# GD32G5x3 register map
File version: 1.0
CPU: CM33 r2p1, little endian, MPU, FPU, 4 interrupt priority bits
Registers are 32-bit, read-write, reset 0x0 unless marked. A register's access mark holds for its fields unless they carry their own. Offsets are from the block's base; [hi:lo] are bit positions; {n}, {i} and the like mark numbered series.

## HRTIMER_COMMON
Base 0x40015B80
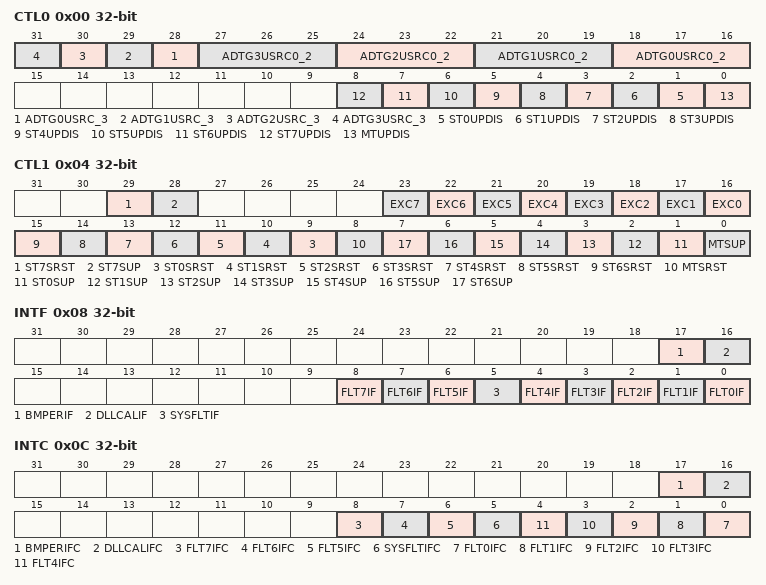
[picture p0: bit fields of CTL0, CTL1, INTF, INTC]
0x00 CTL0 — HRTIMER control register 0
  [n+28] ADTG{n}USRC_3 (n=0..3) — HRTIMER_ADTRIG{n} update source
  [3n+18:3n+16] ADTG{n}USRC0_2 (n=0..3) — HRTIMER_ADTRIG{n} update source
  [n+1] ST{n}UPDIS (n=0..7) — Slave_TIMER{n} update disable
  [0] MTUPDIS — Master_TIMER update disable
0x04 CTL1 — HRTIMER control register 1
  [29] ST7SRST — Slave_TIMER7 software reset
  [28] ST7SUP — Slave_TIMER7 software update
  [n+16] EXC{n} (n=0..7) — Exchange Slave_TIMER{n} outputs
  [n+9] ST{n}SRST (n=0..6) — Slave_TIMER{n} software reset
  [8] MTSRST — Master_TIMER software reset
  [n+1] ST{n}SUP (n=0..6) — Slave_TIMER{n} software update
  [0] MTSUP — Master_TIMER software update
0x08 INTF ro — HRTIMER interrupt flag register
  [17] BMPERIF — Bunch mode period interrupt flag
  [16] DLLCALIF — DLL calibration completed interrupt flag
  [8] FLT7IF — Fault 7 interrupt flag
  [7] FLT6IF — Fault 6 interrupt flag
  [6] FLT5IF — Fault 5 interrupt flag
  [5] SYSFLTIF — System fault interrupt flag
  [n] FLT{n}IF (n=0..4) — Fault {n} interrupt flag
0x0C INTC wo — HRTIMER interrupt flag clear register
  [17] BMPERIFC — Clear bunch mode period interrupt flag
  [16] DLLCALIFC — Clear DLL calibration completed interrupt flag
  [8] FLT7IFC — Clear fault 7 interrupt flag
  [7] FLT6IFC — Clear fault 6 interrupt flag
  [6] FLT5IFC — Clear fault 5 interrupt flag
  [5] SYSFLTIFC — Clear system fault interrupt flag
  [n] FLT{n}IFC (n=0..4) — Clear fault {n} interrupt flag
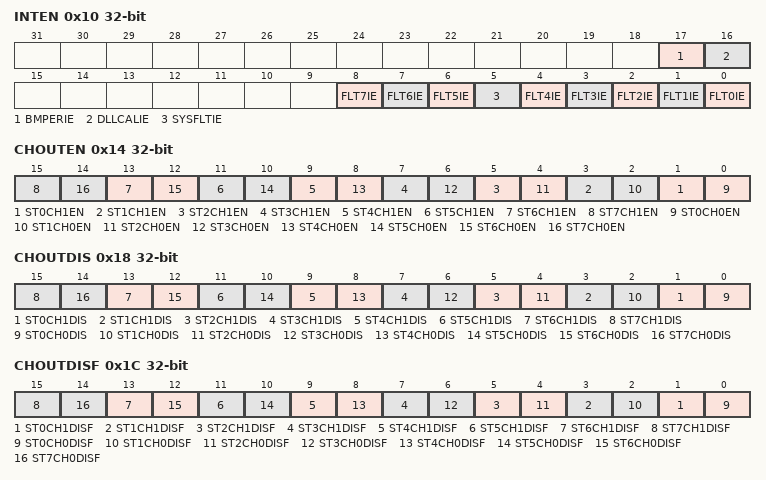
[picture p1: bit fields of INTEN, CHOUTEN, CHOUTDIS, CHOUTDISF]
0x10 INTEN — HRTIMER interrupt enable register
  [17] BMPERIE — Bunch mode period interrupt enable
  [16] DLLCALIE — DLL calibration completed interrupt enable
  [8] FLT7IE — fault 7 interrupt enable
  [7] FLT6IE — fault 6 interrupt enable
  [6] FLT5IE — fault 5 interrupt enable
  [5] SYSFLTIE — System fault interrupt enable
  [n] FLT{n}IE (n=0..4) — fault {n} interrupt enable
0x14 CHOUTEN — HRTIMER channel output enable register
  [2n+1] ST{n}CH1EN (n=0..7) — Slave_TIMER{n} channel 1 output (ST{n}CH1_O) enable
  [2n] ST{n}CH0EN (n=0..7) — Slave_TIMER{n} channel 0 output (ST{n}CH0_O) enable
0x18 CHOUTDIS wo — HRTIMER channel output disable register
  [2n+1] ST{n}CH1DIS (n=0..7) — Slave_TIMER{n} channel 1 output (ST{n}CH1_O) disable
  [2n] ST{n}CH0DIS (n=0..7) — Slave_TIMER{n} channel 0 output (ST{n}CH0_O) disable
0x1C CHOUTDISF ro — HRTIMER channel output disable flag register
  [2n+1] ST{n}CH1DISF (n=0..7) — Slave_TIMER{n} channel 1 output (ST{n}CH1_O) disable flag
  [2n] ST{n}CH0DISF (n=0..7) — Slave_TIMER{n} channel 0 output (ST{n}CH0_O) disable flag
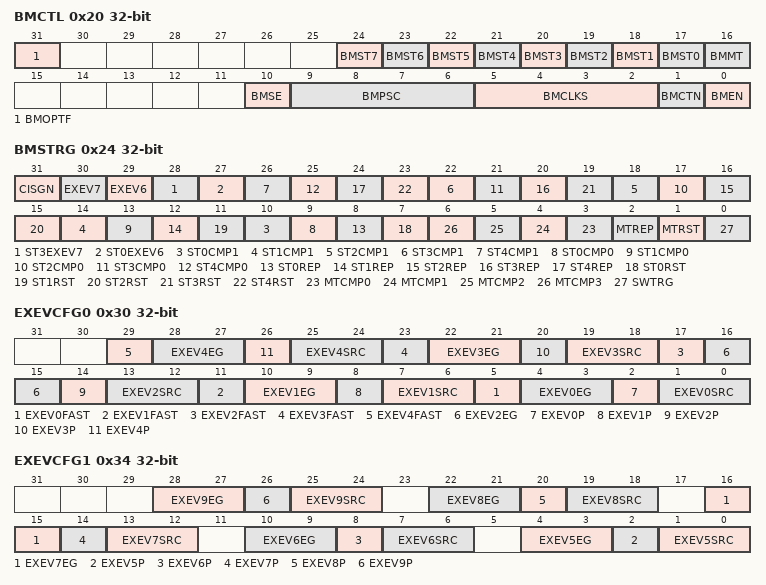
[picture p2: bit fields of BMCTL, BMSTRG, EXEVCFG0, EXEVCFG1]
0x20 BMCTL — HRTIMER bunch mode control register
  [31] BMOPTF — Bunch mode operating flag
  [n+17] BMST{n} (n=0..7) — Slave_TIMER{n} bunch mode
  [16] BMMT — Master_TIMER bunch mode
  [10] BMSE — Bunch mode shadow enable
  [9:6] BMPSC — Bunch mode clock division
  [5:2] BMCLKS — Bunch mode clock source
  [1] BMCTN — Continuous mode in bunch mode
  [0] BMEN — Bunch mode enable
0x24 BMSTRG — HRTIMER bunch mode start trigger register
  [31] CISGN — Chip internal signal triggers bunch mode operation
  [30] EXEV7 — External event 7 triggers bunch mode operation
  [29] EXEV6 — External event 6 triggers bunch mode operation
  [28] ST3EXEV7 — Slave_TIMER3 period event following external event 7 triggers bunch mode operation
  [27] ST0EXEV6 — Slave_TIMER0 period event following external event 6 triggers bunch mode operation
  [4n+10] ST{n}CMP1 (n=0..4) — Slave_TIMER{n} compare 1 event triggers bunch mode operation
  [4n+9] ST{n}CMP0 (n=0..4) — Slave_TIMER{n} compare 0 event triggers bunch mode operation
  [4n+8] ST{n}REP (n=0..4) — Slave_TIMER{n} repetition event triggers bunch mode operation
  [4n+7] ST{n}RST (n=0..4) — Slave_TIMER{n} reset event triggers bunch mode operation
  [n+3] MTCMP{n} (n=0..3) — Master_TIMER compare {n} event triggers bunch mode operation
  [2] MTREP — Master_TIMER repetition event triggers bunch mode operation
  [1] MTRST — Master_TIMER reset event triggers bunch mode operation
  [0] SWTRG — Software triggers bunch mode operation
0x28 BMCMPV — HRTIMER bunch mode compare value register
  [15:0] BMCMPVAL — Bunch mode compare value
0x2C BMCAR — HRTIMER bunch mode counter auto reload register
  [15:0] BMCARL — Bunch mode counter auto reload value
0x30 EXEVCFG0 — HRTIMER external event configuration register 0
  [6n+5] EXEV{n}FAST (n=0..4) — External Event {n} fast mode
  [6n+4:6n+3] EXEV{n}EG (n=0..4) — External event {n} edge sensitivity
  [6n+2] EXEV{n}P (n=0..4) — External event {n} polarity
  [6n+1:6n] EXEV{n}SRC (n=0..4) — External event {n} source
0x34 EXEVCFG1 — HRTIMER external event configuration register 1
  [6n-26:6n-27] EXEV{n}EG (n=5..9) — External event {n} edge sensitivity
  [6n-28] EXEV{n}P (n=5..9) — External event {n} polarity
  [6n-29:6n-30] EXEV{n}SRC (n=5..9) — External event {n} source
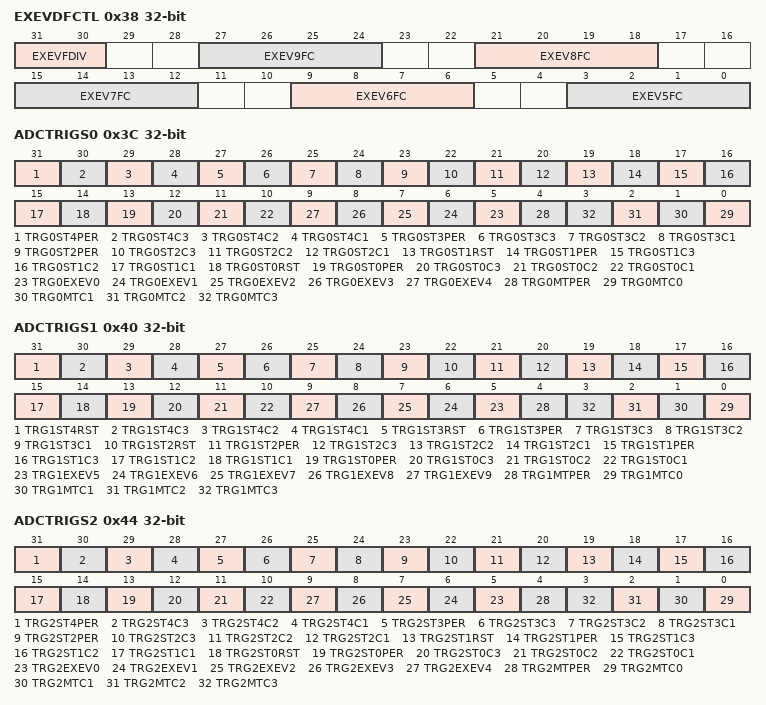
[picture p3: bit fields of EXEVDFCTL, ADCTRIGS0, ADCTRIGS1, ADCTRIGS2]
0x38 EXEVDFCTL — HRTIMER external event digital filter control register
  [31:30] EXEVFDIV — External event clock division
  [6n-27:6n-30] EXEV{n}FC (n=5..9) — External event {n} filter control
0x3C ADCTRIGS0 — HRTIMER trigger source 0 to ADC register
  [31] TRG0ST4PER — HRTIMER_ADCTRIG0 on Slave_TIMER4 period event
  [30] TRG0ST4C3 — HRTIMER_ADCTRIG0 on Slave_TIMER4 compare 3 event
  [29] TRG0ST4C2 — HRTIMER_ADCTRIG0 on Slave_TIMER4 compare 2 event
  [28] TRG0ST4C1 — HRTIMER_ADCTRIG0 on Slave_TIMER4 compare 1 event
  [27] TRG0ST3PER — HRTIMER_ADCTRIG0 on Slave_TIMER3 period event
  [26] TRG0ST3C3 — HRTIMER_ADCTRIG0 on Slave_TIMER3 compare 3 event
  [25] TRG0ST3C2 — HRTIMER_ADCTRIG0 on Slave_TIMER3 compare 2 event
  [24] TRG0ST3C1 — HRTIMER_ADCTRIG0 on Slave_TIMER3 compare 1 event
  [23] TRG0ST2PER — HRTIMER_ADCTRIG0 on Slave_TIMER2 period event
  [22] TRG0ST2C3 — HRTIMER_ADCTRIG0 on Slave_TIMER2 compare 3 event
  [21] TRG0ST2C2 — HRTIMER_ADCTRIG0 on Slave_TIMER2 compare 2 event
  [20] TRG0ST2C1 — HRTIMER_ADCTRIG0 on Slave_TIMER2 compare 1 event
  [19] TRG0ST1RST — HRTIMER_ADCTRIG0 on Slave_TIMER1 reset
  [18] TRG0ST1PER — HRTIMER_ADCTRIG0 on Slave_TIMER1 period event
  [17] TRG0ST1C3 — HRTIMER_ADCTRIG0 on Slave_TIMER1 compare 3 event
  [16] TRG0ST1C2 — HRTIMER_ADCTRIG0 on Slave_TIMER1 compare 2 event
  [15] TRG0ST1C1 — HRTIMER_ADCTRIG0 on Slave_TIMER1 compare 1 event
  [14] TRG0ST0RST — HRTIMER_ADCTRIG0 on Slave_TIMER0 reset
  [13] TRG0ST0PER — HRTIMER_ADCTRIG0 on Slave_TIMER0 period event
  [12] TRG0ST0C3 — HRTIMER_ADCTRIG0 on Slave_TIMER0 compare 3 event
  [11] TRG0ST0C2 — HRTIMER_ADCTRIG0 on Slave_TIMER0 compare 2 event
  [10] TRG0ST0C1 — HRTIMER_ADCTRIG0 on Slave_TIMER0 compare 1 event
  [n+5] TRG0EXEV{n} (n=0..4) — HRTIMER_ADCTRIG0 on external event {n}
  [4] TRG0MTPER — HRTIMER_ADCTRIG0 on Master_TIMER period event
  [n] TRG0MTC{n} (n=0..3) — HRTIMER_ADCTRIG0 on Master_TIMER compare {n} event
0x40 ADCTRIGS1 — HRTIMER trigger source 1 to ADC register
  [31] TRG1ST4RST — HRTIMER_ADCTRIG1 on Slave_TIMER4 reset
  [30] TRG1ST4C3 — HRTIMER_ADCTRIG1 on Slave_TIMER4 compare 3 event
  [29] TRG1ST4C2 — HRTIMER_ADCTRIG1 on Slave_TIMER4 compare 2 event
  [28] TRG1ST4C1 — HRTIMER_ADCTRIG1 on Slave_TIMER4 compare 1 event
  [27] TRG1ST3RST — HRTIMER_ADCTRIG1 on Slave_TIMER3 reset
  [26] TRG1ST3PER — HRTIMER_ADCTRIG1 on Slave_TIMER3 period event
  [25] TRG1ST3C3 — HRTIMER_ADCTRIG1 on Slave_TIMER3 compare 3 event
  [24] TRG1ST3C2 — HRTIMER_ADCTRIG1 on Slave_TIMER3 compare 2 event
  [23] TRG1ST3C1 — HRTIMER_ADCTRIG1 on Slave_TIMER3 compare 1 event
  [22] TRG1ST2RST — HRTIMER_ADCTRIG1 on Slave_TIMER2 reset
  [21] TRG1ST2PER — HRTIMER_ADCTRIG1 on Slave_TIMER2 period event
  [20] TRG1ST2C3 — HRTIMER_ADCTRIG1 on Slave_TIMER2 compare 3 event
  [19] TRG1ST2C2 — HRTIMER_ADCTRIG1 on Slave_TIMER2 compare 2 event
  [18] TRG1ST2C1 — HRTIMER_ADCTRIG1 on Slave_TIMER2 compare 1 event
  [17] TRG1ST1PER — HRTIMER_ADCTRIG1 on Slave_TIMER1 period event
  [16] TRG1ST1C3 — HRTIMER_ADCTRIG1 on Slave_TIMER1 compare 3 event
  [15] TRG1ST1C2 — HRTIMER_ADCTRIG1 on Slave_TIMER1 compare 2 event
  [14] TRG1ST1C1 — HRTIMER_ADCTRIG1 on Slave_TIMER1 compare 1 event
  [13] TRG1ST0PER — HRTIMER_ADCTRIG1 on Slave_TIMER0 period event
  [12] TRG1ST0C3 — HRTIMER_ADCTRIG1 on Slave_TIMER0 compare 3 event
  [11] TRG1ST0C2 — HRTIMER_ADCTRIG1 on Slave_TIMER0 compare 2 event
  [10] TRG1ST0C1 — HRTIMER_ADCTRIG1 on Slave_TIMER0 compare 1 event
  [n] TRG1EXEV{n} (n=5..9) — HRTIMER_ADCTRIG1 on external event {n}
  [4] TRG1MTPER — HRTIMER_ADCTRIG1 on Master_TIMER period event
  [n] TRG1MTC{n} (n=0..3) — HRTIMER_ADCTRIG1 on Master_TIMER compare {n} event
0x44 ADCTRIGS2 — HRTIMER trigger source 2 to ADC register
  [31] TRG2ST4PER — HRTIMER_ADCTRIG2 on Slave_TIMER4 period event
  [30] TRG2ST4C3 — HRTIMER_ADCTRIG2 on Slave_TIMER4 compare 3 event
  [29] TRG2ST4C2 — HRTIMER_ADCTRIG2 on Slave_TIMER4 compare 2 event
  [28] TRG2ST4C1 — HRTIMER_ADCTRIG2 on Slave_TIMER4 compare 1 event
  [27] TRG2ST3PER — HRTIMER_ADCTRIG2 on Slave_TIMER3 period event
  [26] TRG2ST3C3 — HRTIMER_ADCTRIG2 on Slave_TIMER3 compare 3 event
  [25] TRG2ST3C2 — HRTIMER_ADCTRIG2 on Slave_TIMER3 compare 2 event
  [24] TRG2ST3C1 — HRTIMER_ADCTRIG2 on Slave_TIMER3 compare 1 event
  [23] TRG2ST2PER — HRTIMER_ADCTRIG2 on Slave_TIMER2 period event
  [22] TRG2ST2C3 — HRTIMER_ADCTRIG2 on Slave_TIMER2 compare 3 event
  [21] TRG2ST2C2 — HRTIMER_ADCTRIG2 on Slave_TIMER2 compare 2 event
  [20] TRG2ST2C1 — HRTIMER_ADCTRIG2 on Slave_TIMER2 compare 1 event
  [19] TRG2ST1RST — HRTIMER_ADCTRIG2 on Slave_TIMER1 reset
  [18] TRG2ST1PER — HRTIMER_ADCTRIG2 on Slave_TIMER1 period event
  [17] TRG2ST1C3 — HRTIMER_ADCTRIG2 on Slave_TIMER1 compare 3 event
  [16] TRG2ST1C2 — HRTIMER_ADCTRIG2 on Slave_TIMER1 compare 2 event
  [15] TRG2ST1C1 — HRTIMER_ADCTRIG2 on Slave_TIMER1 compare 1 event
  [14] TRG2ST0RST — HRTIMER_ADCTRIG2 on Slave_TIMER0 reset
  [13] TRG2ST0PER — HRTIMER_ADCTRIG2 on Slave_TIMER0 period event
  [12] TRG2ST0C3 — HRTIMER_ADCTRIG2 on Slave_TIMER0 compare 3 event
  [11] TRG2ST0C2 — HRTIMER_ADCTRIG2 on Slave_TIMER0 compare 2 event
  [10] TRG2ST0C1 — HRTIMER_ADCTRIG2 on Slave_TIMER0 compare 1 event
  [n+5] TRG2EXEV{n} (n=0..4) — HRTIMER_ADCTRIG2 on external event {n}
  [4] TRG2MTPER — HRTIMER_ADCTRIG2 on Master_TIMER period event
  [n] TRG2MTC{n} (n=0..3) — HRTIMER_ADCTRIG2 on Master_TIMER compare {n} event
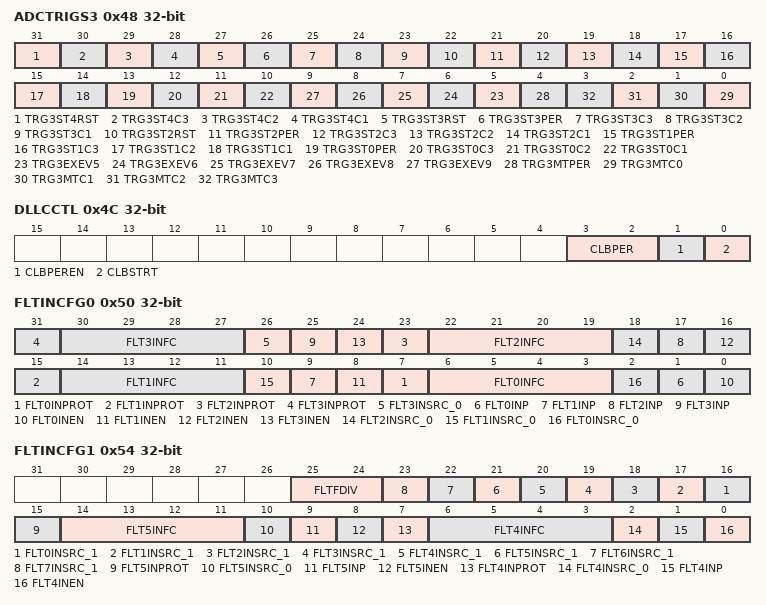
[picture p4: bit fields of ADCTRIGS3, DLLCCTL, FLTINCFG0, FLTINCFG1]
0x48 ADCTRIGS3 — HRTIMER trigger source 3 to ADC register
  [31] TRG3ST4RST — HRTIMER_ADCTRG3 on Slave_TIMER4 reset
  [30] TRG3ST4C3 — HRTIMER_ADCTRG3 on Slave_TIMER4 compare 3 event
  [29] TRG3ST4C2 — HRTIMER_ADCTRG3 on Slave_TIMER4 compare 2 event
  [28] TRG3ST4C1 — HRTIMER_ADCTRG3 on Slave_TIMER4 compare 1 event
  [27] TRG3ST3RST — HRTIMER_ADCTRG3 on Slave_TIMER3 reset
  [26] TRG3ST3PER — HRTIMER_ADCTRG3 on Slave_TIMER3 period event
  [25] TRG3ST3C3 — HRTIMER_ADCTRG3 on Slave_TIMER3 compare 3 event
  [24] TRG3ST3C2 — HRTIMER_ADCTRG3 on Slave_TIMER3 compare 2 event
  [23] TRG3ST3C1 — HRTIMER_ADCTRG3 on Slave_TIMER3 compare 1 event
  [22] TRG3ST2RST — HRTIMER_ADCTRG3 on Slave_TIMER2 reset
  [21] TRG3ST2PER — HRTIMER_ADCTRG3 on Slave_TIMER2 period event
  [20] TRG3ST2C3 — HRTIMER_ADCTRG3 on Slave_TIMER2 compare 3 event
  [19] TRG3ST2C2 — HRTIMER_ADCTRG3 on Slave_TIMER2 compare 2 event
  [18] TRG3ST2C1 — HRTIMER_ADCTRG3 on Slave_TIMER2 compare 1 event
  [17] TRG3ST1PER — HRTIMER_ADCTRG3 on Slave_TIMER1 period event
  [16] TRG3ST1C3 — HRTIMER_ADCTRG3 on Slave_TIMER1 compare 3 event
  [15] TRG3ST1C2 — HRTIMER_ADCTRG3 on Slave_TIMER1 compare 2 event
  [14] TRG3ST1C1 — HRTIMER_ADCTRG3 on Slave_TIMER1 compare 1 event
  [13] TRG3ST0PER — HRTIMER_ADCTRG3 on Slave_TIMER0 period event
  [12] TRG3ST0C3 — HRTIMER_ADCTRG3 on Slave_TIMER0 compare 3 event
  [11] TRG3ST0C2 — HRTIMER_ADCTRG3 on Slave_TIMER0 compare 2 event
  [10] TRG3ST0C1 — HRTIMER_ADCTRG3 on Slave_TIMER0 compare 1 event
  [n] TRG3EXEV{n} (n=5..9) — HRTIMER_ADCTRG3 on external event {n}
  [4] TRG3MTPER — HRTIMER_ADCTRG3 on Master_TIMER period event
  [n] TRG3MTC{n} (n=0..3) — HRTIMER_ADCTRG3 on Master_TIMER compare {n} event
0x4C DLLCCTL access per field — HRTIMER DLL calibration control register
  [3:2] CLBPER rw — DLL calibration period
  [1] CLBPEREN rw — DLL periodic calibration enable
  [0] CLBSTRT wo — DLL calibration start once
0x50 FLTINCFG0 — HRTIMER fault input configuration register 0
  [8n+7] FLT{n}INPROT (n=0..3) — Protect fault {n} input configuration
  [8n+6:8n+3] FLT{n}INFC (n=0..3) — Fault {n} input filter control
  [26] FLT3INSRC_0 — Fault 3 input source
  [8n+1] FLT{n}INP (n=0..3) — Fault {n} input polarity
  [8n] FLT{n}INEN (n=0..3) — Fault {n} input enable
  [18] FLT2INSRC_0 — Fault 2 input source
  [10] FLT1INSRC_0 — Fault 1 input source
  [2] FLT0INSRC_0 — Fault 0 input source, combine with FLT0INSRC[1]
0x54 FLTINCFG1 — HRTIMER fault input configuration register 1
  [25:24] FLTFDIV — Fault input clock division
  [n+16] FLT{n}INSRC_1 (n=0..7) — Fault {n} input source
  [15] FLT5INPROT — Protect fault 5 input configuration
  [14:11] FLT5INFC — Fault 5 input filter control
  [10] FLT5INSRC_0 — Fault 5 input source
  [9] FLT5INP — Fault 5 input polarity
  [8] FLT5INEN — Fault 5 input enable
  [7] FLT4INPROT — Protect fault 4 input configuration
  [6:3] FLT4INFC — Fault 4 input filter control
  [2] FLT4INSRC_0 — Fault 4 input source
  [1] FLT4INP — Fault 4 input polarity
  [0] FLT4INEN — Fault 4 input enable
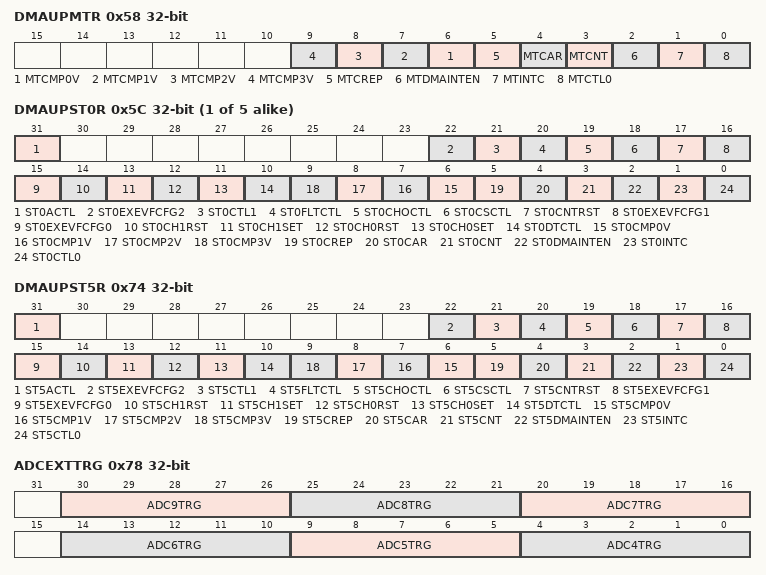
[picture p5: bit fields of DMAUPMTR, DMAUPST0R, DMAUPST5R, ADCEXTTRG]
0x58 DMAUPMTR — HRTIMER DMA update Master_TIMER register
  [n+6] MTCMP{n}V (n=0..3) — HRTIMER_MTCMP{n}V update by DMA mode
  [5] MTCREP — HRTIMER_MTCREP update by DMA mode
  [4] MTCAR — HRTIMER_MTCAR update by DMA mode
  [3] MTCNT — HRTIMER_MTCNT update by DMA mode
  [2] MTDMAINTEN — HRTIMER_MTDMAINTEN update by DMA mode
  [1] MTINTC — HRTIMER_MTINTC update by DMA mode
  [0] MTCTL0 — HRTIMER_MTCTL0 update by DMA mode
{0x5C+4i} DMAUPST{i}R (i=0..4) — HRTIMER DMA update Slave_TIMERx regist {i}
  [31] ST{i}ACTL — HRTIMER_ST{i}ACTL update by DMA mode
  [22] ST{i}EXEVFCFG2 — HRTIMER_ST{i}EXEVFCFG2 update by DMA mode
  [21] ST{i}CTL1 — HRTIMER_ST{i}CTL1 update by DMA mode
  [20] ST{i}FLTCTL — HRTIMER_ST{i}FLTCTL update by DMA mode
  [19] ST{i}CHOCTL — HRTIMER_ST{i}CHOCTL update by DMA mode
  [18] ST{i}CSCTL — HRTIMER_ST{i}CSCTL update by DMA mode
  [17] ST{i}CNTRST — HRTIMER_ST{i}CNTRST update by DMA mode
  [16] ST{i}EXEVFCFG1 — HRTIMER_ST{i}EXEVFCFG1update by DMA mode
  [15] ST{i}EXEVFCFG0 — HRTIMER_ST{i}EXEVFCFG0update by DMA mode
  [14] ST{i}CH1RST — HRTIMER_ST{i}CH1RST update by DMA mode
  [13] ST{i}CH1SET — HRTIMER_ST{i}CH1SET update by DMA mode
  [12] ST{i}CH0RST — HRTIMER_ST{i}CH0RST update by DMA mode
  [11] ST{i}CH0SET — HRTIMER_ST{i}CH0SET update by DMA mode
  [10] ST{i}DTCTL — HRTIMER_ST{i}DTCTL update by DMA mode
  [n+6] ST{i}CMP{n}V (n=0..3) — HRTIMER_ST{i}CMP{n}V update by DMA mode
  [5] ST{i}CREP — HRTIMER_ST{i}CREP update by DMA mode
  [4] ST{i}CAR — HRTIMER_ST{i}CAR update by DMA mode
  [3] ST{i}CNT — HRTIMER_ST{i}CNT update by DMA mode
  [2] ST{i}DMAINTEN — HRTIMER_ST{i}DMAINTEN update by DMA mode
  [1] ST{i}INTC — HRTIMER_ST{i}INTC update by DMA mode
  [0] ST{i}CTL0 — HRTIMER_ST{i}CTL0 update by DMA mode
0x70 DMATB wo — HRTIMER DMA transfer buffer register
  [31:0] DMATB — DMA transfer buffer
0x74 DMAUPST5R — HRTIMER DMA update Slave_TIMERx regist 5
  [31] ST5ACTL — HRTIMER_ST5ACTL update by DMA mode
  [22] ST5EXEVFCFG2 — HRTIMER_ST5EXEVFCFG2 update by DMA mode
  [21] ST5CTL1 — HRTIMER_ST5CTL1 update by DMA mode
  [20] ST5FLTCTL — HRTIMER_ST5FLTCTL update by DMA mode
  [19] ST5CHOCTL — HRTIMER_ST5CHOCTL update by DMA mode
  [18] ST5CSCTL — HRTIMER_ST5CSCTL update by DMA mode
  [17] ST5CNTRST — HRTIMER_ST5CNTRST update by DMA mode
  [16] ST5EXEVFCFG1 — HRTIMER_ST5EXEVFCFG1update by DMA mode
  [15] ST5EXEVFCFG0 — HRTIMER_ST5EXEVFCFG0update by DMA mode
  [14] ST5CH1RST — HRTIMER_ST5CH1RST update by DMA mode
  [13] ST5CH1SET — HRTIMER_ST5CH1SET update by DMA mode
  [12] ST5CH0RST — HRTIMER_ST5CH0RST update by DMA mode
  [11] ST5CH0SET — HRTIMER_ST5CH0SET update by DMA mode
  [10] ST5DTCTL — HRTIMER_ST5DTCTL update by DMA mode
  [n+6] ST5CMP{n}V (n=0..3) — HRTIMER_ST5CMP{n}V update by DMA mode
  [5] ST5CREP — HRTIMER_ST5CREP update by DMA mode
  [4] ST5CAR — HRTIMER_ST5CAR update by DMA mode
  [3] ST5CNT — HRTIMER_ST5CNT update by DMA mode
  [2] ST5DMAINTEN — HRTIMER_ST5DMAINTEN update by DMA mode
  [1] ST5INTC — HRTIMER_ST5INTC update by DMA mode
  [0] ST5CTL0 — HRTIMER_ST5CTL0 update by DMA mode
0x78 ADCEXTTRG — HRTIMER ADC extended trigger register
  [30:26] ADC9TRG — ADC trigger 9 selection This bit selects the ADC trigger 9 source
  [25:21] ADC8TRG — ADC trigger 8 selection This bit selects the ADC trigger 8 source
  [20:16] ADC7TRG — ADC trigger 7 selection This bit selects the ADC trigger 7 source
  [14:10] ADC6TRG — ADC trigger 6 selection This bit selects the ADC trigger 6 source
  [9:5] ADC5TRG — ADC trigger 5 selection This bit selects the ADC trigger 5 source
  [4:0] ADC4TRG — ADC trigger 4 selection This bit selects the ADC trigger 4 source
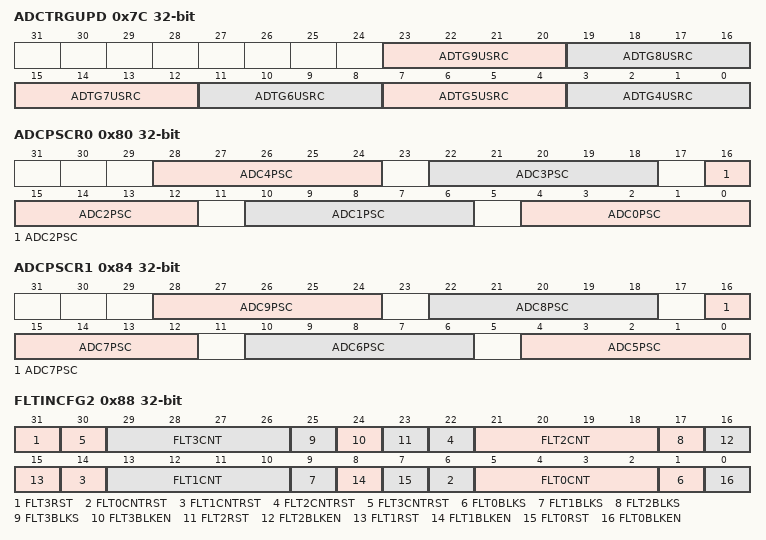
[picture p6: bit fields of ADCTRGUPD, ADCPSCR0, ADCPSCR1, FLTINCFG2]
0x7C ADCTRGUPD — HRTIMER ADC trigger update register
  [23:20] ADTG9USRC — ADC trigger 9 update source
  [19:16] ADTG8USRC — ADC trigger 8 update source
  [15:12] ADTG7USRC — ADC trigger 7 update source
  [11:8] ADTG6USRC — ADC trigger 6update source
  [7:4] ADTG5USRC — ADC trigger5 update source
  [3:0] ADTG4USRC — ADC4TRG update source
0x80 ADCPSCR0 — HRTIMER ADC post scaler registe register 0
  [6n+4:6n] ADC{n}PSC (n=0..4) — ADC trigger {n} prescaler
0x84 ADCPSCR1 — HRTIMER ADC post scaler registe register 1
  [6n-26:6n-30] ADC{n}PSC (n=5..9) — ADC trigger {n} prescaler
0x88 FLTINCFG2 — HRTIMER fault input configuration register 2
  [31] FLT3RST — Fault 3 reset mode
  [8n+6] FLT{n}CNTRST (n=0..3) — Fault {n} counter reset
  [29:26] FLT3CNT — Fault 3 counter
  [8n+1] FLT{n}BLKS (n=0..3) — Fault {n} blanking source
  [24] FLT3BLKEN — Fault 3 blanking enable
  [23] FLT2RST — Fault 2 reset mode
  [21:18] FLT2CNT — Fault 2 counter
  [16] FLT2BLKEN — Fault 3 blanking enable
  [15] FLT1RST — Fault 1 reset mode
  [13:10] FLT1CNT — Fault 1 counter
  [8] FLT1BLKEN — Fault 1 blanking enable
  [7] FLT0RST — Fault 0 reset mode:
  [5:2] FLT0CNT — Fault 0 Counter:
  [0] FLT0BLKEN — Fault 0 blanking enable
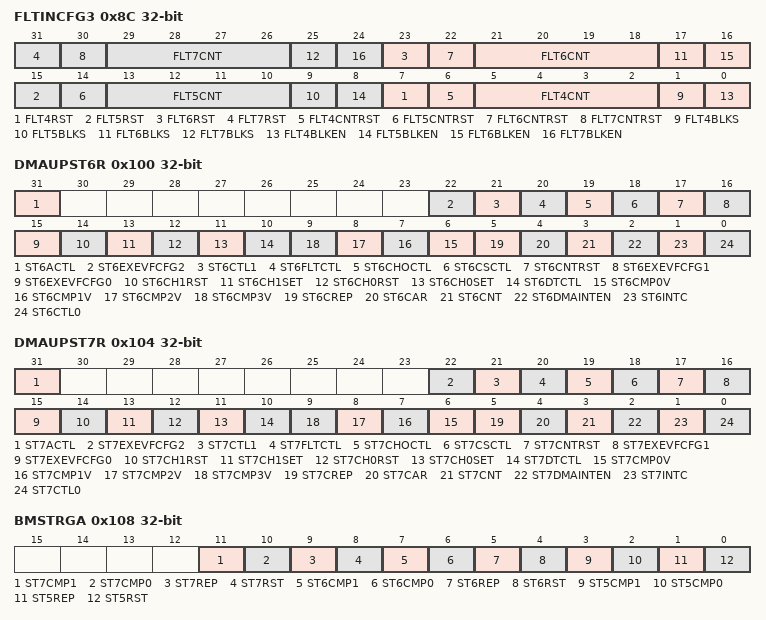
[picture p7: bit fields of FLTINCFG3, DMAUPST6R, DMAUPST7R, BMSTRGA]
0x8C FLTINCFG3 — HRTIMER fault input configuration register 3
  [8n-25] FLT{n}RST (n=4..7) — Fault {n} reset mode
  [8n-26] FLT{n}CNTRST (n=4..7) — Fault {n} counter reset
  [8n-27:8n-30] FLT{n}CNT (n=4..7) — Fault {n} counter
  [8n-31] FLT{n}BLKS (n=4..7) — Fault {n} blanking source
  [8n-32] FLT{n}BLKEN (n=4..7) — Fault {n} blanking enable
0x100 DMAUPST6R — HRTIMER DMA update Slave_TIMERx regist 6
  [31] ST6ACTL — HRTIMER_ST6ACTL update by DMA mode
  [22] ST6EXEVFCFG2 — HRTIMER_ST6EXEVFCFG2 update by DMA mode
  [21] ST6CTL1 — HRTIMER_ST6CTL1 update by DMA mode
  [20] ST6FLTCTL — HRTIMER_ST6FLTCTL update by DMA mode
  [19] ST6CHOCTL — HRTIMER_ST6CHOCTL update by DMA mode
  [18] ST6CSCTL — HRTIMER_ST6CSCTL update by DMA mode
  [17] ST6CNTRST — HRTIMER_ST6CNTRST update by DMA mode
  [16] ST6EXEVFCFG1 — HRTIMER_ST6EXEVFCFG1update by DMA mode
  [15] ST6EXEVFCFG0 — HRTIMER_ST6EXEVFCFG0update by DMA mode
  [14] ST6CH1RST — HRTIMER_ST6CH1RST update by DMA mode
  [13] ST6CH1SET — HRTIMER_ST6CH1SET update by DMA mode
  [12] ST6CH0RST — HRTIMER_ST6CH0RST update by DMA mode
  [11] ST6CH0SET — HRTIMER_ST6CH0SET update by DMA mode
  [10] ST6DTCTL — HRTIMER_ST6DTCTL update by DMA mode
  [n+6] ST6CMP{n}V (n=0..3) — HRTIMER_ST6CMP{n}V update by DMA mode
  [5] ST6CREP — HRTIMER_ST6CREP update by DMA mode
  [4] ST6CAR — HRTIMER_ST6CAR update by DMA mode
  [3] ST6CNT — HRTIMER_ST6CNT update by DMA mode
  [2] ST6DMAINTEN — HRTIMER_ST6DMAINTEN update by DMA mode
  [1] ST6INTC — HRTIMER_ST6INTC update by DMA mode
  [0] ST6CTL0 — HRTIMER_ST6CTL0 update by DMA mode
0x104 DMAUPST7R — HRTIMER DMA update Slave_TIMERx regist 7
  [31] ST7ACTL — HRTIMER_ST7ACTL update by DMA mode
  [22] ST7EXEVFCFG2 — HRTIMER_ST7EXEVFCFG2 update by DMA mode
  [21] ST7CTL1 — HRTIMER_ST7CTL1 update by DMA mode
  [20] ST7FLTCTL — HRTIMER_ST7FLTCTL update by DMA mode
  [19] ST7CHOCTL — HRTIMER_ST7CHOCTL update by DMA mode
  [18] ST7CSCTL — HRTIMER_ST7CSCTL update by DMA mode
  [17] ST7CNTRST — HRTIMER_ST7CNTRST update by DMA mode
  [16] ST7EXEVFCFG1 — HRTIMER_ST7EXEVFCFG1update by DMA mode
  [15] ST7EXEVFCFG0 — HRTIMER_ST7EXEVFCFG0update by DMA mode
  [14] ST7CH1RST — HRTIMER_ST7CH1RST update by DMA mode
  [13] ST7CH1SET — HRTIMER_ST7CH1SET update by DMA mode
  [12] ST7CH0RST — HRTIMER_ST7CH0RST update by DMA mode
  [11] ST7CH0SET — HRTIMER_ST7CH0SET update by DMA mode
  [10] ST7DTCTL — HRTIMER_ST7DTCTL update by DMA mode
  [n+6] ST7CMP{n}V (n=0..3) — HRTIMER_ST7CMP{n}V update by DMA mode
  [5] ST7CREP — HRTIMER_ST7CREP update by DMA mode
  [4] ST7CAR — HRTIMER_ST7CAR update by DMA mode
  [3] ST7CNT — HRTIMER_ST7CNT update by DMA mode
  [2] ST7DMAINTEN — HRTIMER_ST7DMAINTEN update by DMA mode
  [1] ST7INTC — HRTIMER_ST7INTC update by DMA mode
  [0] ST7CTL0 — HRTIMER_ST7CTL0 update by DMA mode
0x108 BMSTRGA — HRTIMER bunch mode start trigger add register
  [11] ST7CMP1 — Slave_TIMER7 compare 1 event triggers bunch mode operation
  [10] ST7CMP0 — Slave_TIMER7 compare 0 event triggers bunch mode operation
  [9] ST7REP — Slave_TIMER7 repetition event triggers bunch mode operation
  [8] ST7RST — Slave_TIMER7 reset event triggers bunch mode operation
  [7] ST6CMP1 — Slave_TIMER6 compare 1 event triggers bunch mode operation
  [6] ST6CMP0 — Slave_TIMER6 compare 0 event triggers bunch mode operation
  [5] ST6REP — Slave_TIMER6 repetition event triggers bunch mode operation
  [4] ST6RST — Slave_TIMER6 reset event triggers bunch mode operation
  [3] ST5CMP1 — Slave_TIMER5 compare 1 event triggers bunch mode operation
  [2] ST5CMP0 — Slave_TIMER5 compare 0 event triggers bunch mode operation
  [1] ST5REP — Slave_TIMER5 repetition event triggers bunch mode operation
  [0] ST5RST — Slave_TIMER5 reset event triggers bunch mode operation
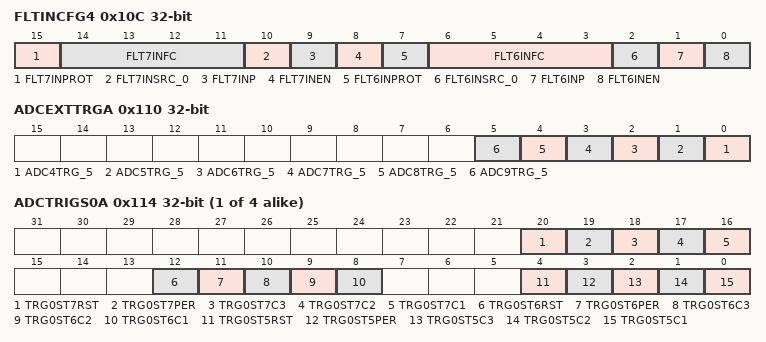
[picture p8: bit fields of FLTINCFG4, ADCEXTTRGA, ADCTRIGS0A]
0x10C FLTINCFG4 — HRTIMER fault input configuration register 4
  [15] FLT7INPROT — Protect fault 7 input configuration
  [14:11] FLT7INFC — Fault 7 input filter control
  [10] FLT7INSRC_0 — Fault 7 input source
  [9] FLT7INP — Fault 7 input polarity
  [8] FLT7INEN — Fault 7 input enable
  [7] FLT6INPROT — Protect fault 6 input configuration
  [6:3] FLT6INFC — Fault 6 input filter control
  [2] FLT6INSRC_0 — Fault 6 input source
  [1] FLT6INP — Fault 6 input polarity
  [0] FLT6INEN — Fault 6 input enable
0x110 ADCEXTTRGA — HRTIMER ADC extended trigger add register
  [n-4] ADC{n}TRG_5 (n=4..9) — ADC trigger {n} selection This bit selects the ADC trigger {n} source
{0x114+4i} ADCTRIGS{i}A (i=0..3) — HRTIMER trigger source {i} to ADC add register
  [20] TRG{i}ST7RST — HRTIMER_ADCTRIG{i} on Slave_TIMER7 reset
  [19] TRG{i}ST7PER — HRTIMER_ADCTRIG{i} on Slave_TIMER7 period event
  [18] TRG{i}ST7C3 — HRTIMER_ADCTRG{i} on Slave_TIMER7 compare 3 event
  [17] TRG{i}ST7C2 — HRTIMER_ADCTRG{i} on Slave_TIMER7 compare 2 event
  [16] TRG{i}ST7C1 — HRTIMER_ADCTRG{i} on Slave_TIMER7 compare 1 event
  [12] TRG{i}ST6RST — HRTIMER_ADCTRIG{i} on Slave_TIMER6 reset
  [11] TRG{i}ST6PER — HRTIMER_ADCTRIG{i} on Slave_TIMER6 period event
  [10] TRG{i}ST6C3 — HRTIMER_ADCTRG{i} on Slave_TIMER6 compare 3 event
  [9] TRG{i}ST6C2 — HRTIMER_ADCTRG{i} on Slave_TIMER6 compare 2 event
  [8] TRG{i}ST6C1 — HRTIMER_ADCTRG{i} on Slave_TIMER6 compare 1 event
  [4] TRG{i}ST5RST — HRTIMER_ADCTRIG{i} on Slave_TIMER5 reset
  [3] TRG{i}ST5PER — HRTIMER_ADCTRIG{i} on Slave_TIMER5 period event
  [2] TRG{i}ST5C3 — HRTIMER_ADCTRG{i} on Slave_TIMER5 compare 3 event
  [1] TRG{i}ST5C2 — HRTIMER_ADCTRG{i} on Slave_TIMER5 compare 2 event
  [0] TRG{i}ST5C1 — HRTIMER_ADCTRG{i} on Slave_TIMER5 compare 1 event
